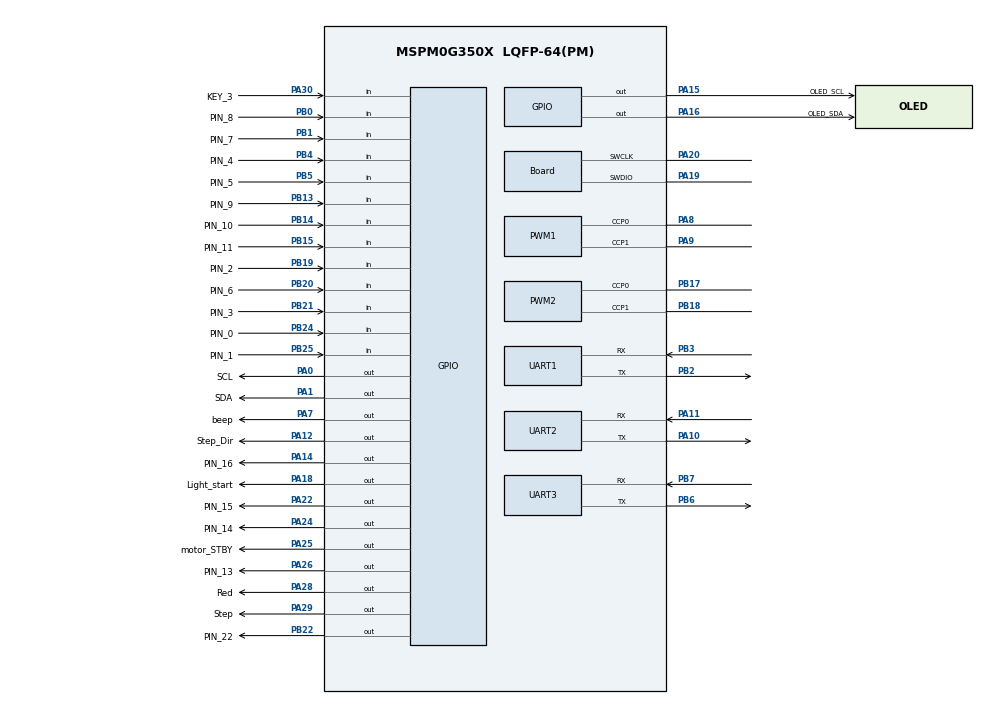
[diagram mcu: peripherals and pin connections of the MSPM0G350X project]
/**
 * @cliArgs --device "MSPM0G350X" --part "Default" --package "LQFP-64(PM)" --product "mspm0_sdk@2.03.00.07"
 * @versions {"tool":"1.22.0+3893"}
 */

/**
 * Import the modules used in this configuration.
 */
const GPIO          = scripting.addModule("/ti/driverlib/GPIO", {}, false);
const GPIO1         = GPIO.addInstance();
const GPIO2         = GPIO.addInstance();
const GPIO3         = GPIO.addInstance();
const GPIO4         = GPIO.addInstance();
const GPIO5         = GPIO.addInstance();
const GPIO6         = GPIO.addInstance();
const GPIO7         = GPIO.addInstance();
const PWM           = scripting.addModule("/ti/driverlib/PWM", {}, false);
const PWM1          = PWM.addInstance();
const PWM2          = PWM.addInstance();
const SYSCTL        = scripting.addModule("/ti/driverlib/SYSCTL");
const TIMER         = scripting.addModule("/ti/driverlib/TIMER", {}, false);
const TIMER1        = TIMER.addInstance();
const UART          = scripting.addModule("/ti/driverlib/UART", {}, false);
const UART1         = UART.addInstance();
const UART2         = UART.addInstance();
const UART3         = UART.addInstance();
const ProjectConfig = scripting.addModule("/ti/project_config/ProjectConfig");

/**
 * Write custom configuration values to the imported modules.
 */
const divider6       = system.clockTree["PLL_CLK2X_DIV"];
divider6.divideValue = 4;

const divider7       = system.clockTree["PLL_PDIV"];
divider7.divideValue = 2;

const divider9       = system.clockTree["UDIV"];
divider9.divideValue = 2;

const gate7  = system.clockTree["MFCLKGATE"];
gate7.enable = true;

const multiplier2         = system.clockTree["PLL_QDIV"];
multiplier2.multiplyValue = 10;

const mux8       = system.clockTree["HSCLKMUX"];
mux8.inputSelect = "HSCLKMUX_SYSPLL2X";

GPIO1.$name                         = "PORTA";
GPIO1.port                          = "PORTA";
GPIO1.associatedPins.create(8);
GPIO1.associatedPins[0].$name       = "OLED_SCL";
GPIO1.associatedPins[0].pin.$assign = "PA15";
GPIO1.associatedPins[1].$name       = "PIN_13";
GPIO1.associatedPins[1].pin.$assign = "PA26";
GPIO1.associatedPins[2].$name       = "PIN_14";
GPIO1.associatedPins[2].pin.$assign = "PA24";
GPIO1.associatedPins[3].$name       = "PIN_15";
GPIO1.associatedPins[3].pin.$assign = "PA22";
GPIO1.associatedPins[4].$name       = "PIN_16";
GPIO1.associatedPins[4].pin.$assign = "PA14";
GPIO1.associatedPins[5].$name       = "beep";
GPIO1.associatedPins[5].pin.$assign = "PA7";
GPIO1.associatedPins[6].$name       = "motor_STBY";
GPIO1.associatedPins[6].pin.$assign = "PA25";
GPIO1.associatedPins[7].$name       = "Light_start";
GPIO1.associatedPins[7].pin.$assign = "PA18";

const Board                       = scripting.addModule("/ti/driverlib/Board", {}, false);
Board.peripheral.$assign          = "DEBUGSS";
Board.peripheral.swclkPin.$assign = "PA20";
Board.peripheral.swdioPin.$assign = "PA19";

GPIO2.$name                         = "PORTB";
GPIO2.port                          = "PORTA";
GPIO2.associatedPins.create(4);
GPIO2.associatedPins[0].$name       = "OLED_SDA";
GPIO2.associatedPins[0].pin.$assign = "PA16";
GPIO2.associatedPins[1].$name       = "Red";
GPIO2.associatedPins[1].pin.$assign = "PA28";
GPIO2.associatedPins[2].$name       = "Step";
GPIO2.associatedPins[2].pin.$assign = "PA29";
GPIO2.associatedPins[3].$name       = "Step_Dir";
GPIO2.associatedPins[3].pin.$assign = "PA12";

GPIO3.$name                               = "GPIO_EncoderA";
GPIO3.port                                = "PORTB";
GPIO3.associatedPins.create(4);
GPIO3.associatedPins[0].$name             = "PIN_0";
GPIO3.associatedPins[0].direction         = "INPUT";
GPIO3.associatedPins[0].interruptEn       = true;
GPIO3.associatedPins[0].interruptPriority = "0";
GPIO3.associatedPins[0].polarity          = "RISE";
GPIO3.associatedPins[0].pin.$assign       = "PB24";
GPIO3.associatedPins[1].$name             = "PIN_1";
GPIO3.associatedPins[1].direction         = "INPUT";
GPIO3.associatedPins[1].polarity          = "RISE";
GPIO3.associatedPins[1].interruptEn       = true;
GPIO3.associatedPins[1].interruptPriority = "0";
GPIO3.associatedPins[1].pin.$assign       = "PB25";
GPIO3.associatedPins[2].$name             = "PIN_2";
GPIO3.associatedPins[2].direction         = "INPUT";
GPIO3.associatedPins[2].interruptEn       = true;
GPIO3.associatedPins[2].polarity          = "RISE";
GPIO3.associatedPins[2].interruptPriority = "0";
GPIO3.associatedPins[2].pin.$assign       = "PB19";
GPIO3.associatedPins[3].$name             = "PIN_3";
GPIO3.associatedPins[3].direction         = "INPUT";
GPIO3.associatedPins[3].interruptEn       = true;
GPIO3.associatedPins[3].interruptPriority = "0";
GPIO3.associatedPins[3].polarity          = "RISE";
GPIO3.associatedPins[3].pin.$assign       = "PB21";

GPIO4.$name                              = "GPIO_KEY";
GPIO4.port                               = "PORTA";
GPIO4.associatedPins.create(3);
GPIO4.associatedPins[0].direction        = "INPUT";
GPIO4.associatedPins[0].internalResistor = "PULL_UP";
GPIO4.associatedPins[0].$name            = "KEY_1";
GPIO4.associatedPins[0].assignedPin      = "27";
GPIO4.associatedPins[1].direction        = "INPUT";
GPIO4.associatedPins[1].internalResistor = "PULL_UP";
GPIO4.associatedPins[1].$name            = "KEY_2";
GPIO4.associatedPins[1].assignedPin      = "17";
GPIO4.associatedPins[2].direction        = "INPUT";
GPIO4.associatedPins[2].internalResistor = "PULL_UP";
GPIO4.associatedPins[2].$name            = "KEY_3";
GPIO4.associatedPins[2].assignedPin      = "30";
GPIO4.associatedPins[2].pin.$assign      = "PA30";

GPIO5.$name                         = "user_led";
GPIO5.port                          = "PORTB";
GPIO5.associatedPins[0].$name       = "PIN_22";
GPIO5.associatedPins[0].assignedPin = "22";
GPIO5.associatedPins[0].pin.$assign = "PB22";

GPIO6.$name                         = "HUIDU";
GPIO6.associatedPins.create(8);
GPIO6.associatedPins[0].$name       = "PIN_4";
GPIO6.associatedPins[0].direction   = "INPUT";
GPIO6.associatedPins[0].pin.$assign = "PB4";
GPIO6.associatedPins[1].$name       = "PIN_5";
GPIO6.associatedPins[1].direction   = "INPUT";
GPIO6.associatedPins[1].pin.$assign = "PB5";
GPIO6.associatedPins[2].$name       = "PIN_6";
GPIO6.associatedPins[2].direction   = "INPUT";
GPIO6.associatedPins[2].pin.$assign = "PB20";
GPIO6.associatedPins[3].$name       = "PIN_7";
GPIO6.associatedPins[3].direction   = "INPUT";
GPIO6.associatedPins[3].pin.$assign = "PB1";
GPIO6.associatedPins[4].$name       = "PIN_8";
GPIO6.associatedPins[4].direction   = "INPUT";
GPIO6.associatedPins[4].pin.$assign = "PB0";
GPIO6.associatedPins[5].$name       = "PIN_9";
GPIO6.associatedPins[5].direction   = "INPUT";
GPIO6.associatedPins[5].pin.$assign = "PB13";
GPIO6.associatedPins[6].$name       = "PIN_10";
GPIO6.associatedPins[6].direction   = "INPUT";
GPIO6.associatedPins[6].assignedPin = "14";
GPIO6.associatedPins[6].pin.$assign = "PB14";
GPIO6.associatedPins[7].$name       = "PIN_11";
GPIO6.associatedPins[7].direction   = "INPUT";
GPIO6.associatedPins[7].pin.$assign = "PB15";

GPIO7.$name                          = "GPIO_PORT";
GPIO7.associatedPins.create(2);
GPIO7.associatedPins[0].$name        = "SDA";
GPIO7.associatedPins[0].assignedPort = "PORTA";
GPIO7.associatedPins[0].assignedPin  = "1";
GPIO7.associatedPins[0].pin.$assign  = "PA1";
GPIO7.associatedPins[1].$name        = "SCL";
GPIO7.associatedPins[1].assignedPort = "PORTA";
GPIO7.associatedPins[1].assignedPin  = "0";
GPIO7.associatedPins[1].pin.$assign  = "PA0";

PWM1.$name                              = "Motor";
PWM1.timerCount                         = 32000;
PWM1.interruptPriority                  = "3";
PWM1.peripheral.$assign                 = "TIMA0";
PWM1.peripheral.ccp0Pin.$assign         = "PA8";
PWM1.peripheral.ccp1Pin.$assign         = "PA9";
PWM1.PWM_CHANNEL_0.$name                = "ti_driverlib_pwm_PWMTimerCC0";
PWM1.PWM_CHANNEL_1.$name                = "ti_driverlib_pwm_PWMTimerCC1";
PWM1.ccp0PinConfig.direction            = scripting.forceWrite("OUTPUT");
PWM1.ccp0PinConfig.hideOutputInversion  = scripting.forceWrite(false);
PWM1.ccp0PinConfig.onlyInternalResistor = scripting.forceWrite(false);
PWM1.ccp0PinConfig.passedPeripheralType = scripting.forceWrite("Digital");
PWM1.ccp0PinConfig.$name                = "ti_driverlib_gpio_GPIOPinGeneric2";
PWM1.ccp1PinConfig.direction            = scripting.forceWrite("OUTPUT");
PWM1.ccp1PinConfig.hideOutputInversion  = scripting.forceWrite(false);
PWM1.ccp1PinConfig.onlyInternalResistor = scripting.forceWrite(false);
PWM1.ccp1PinConfig.passedPeripheralType = scripting.forceWrite("Digital");
PWM1.ccp1PinConfig.$name                = "ti_driverlib_gpio_GPIOPinGeneric3";

PWM2.$name                              = "Steer";
PWM2.timerStartTimer                    = true;
PWM2.clockDivider                       = 4;
PWM2.clockSource                        = "MFCLK";
PWM2.timerCount                         = 20000;
PWM2.peripheral.$assign                 = "TIMA1";
PWM2.peripheral.ccp0Pin.$assign         = "PB17";
PWM2.peripheral.ccp1Pin.$assign         = "PB18";
PWM2.PWM_CHANNEL_0.$name                = "ti_driverlib_pwm_PWMTimerCC2";
PWM2.PWM_CHANNEL_0.invert               = true;
PWM2.PWM_CHANNEL_1.$name                = "ti_driverlib_pwm_PWMTimerCC3";
PWM2.PWM_CHANNEL_1.invert               = true;
PWM2.ccp0PinConfig.direction            = scripting.forceWrite("OUTPUT");
PWM2.ccp0PinConfig.hideOutputInversion  = scripting.forceWrite(false);
PWM2.ccp0PinConfig.onlyInternalResistor = scripting.forceWrite(false);
PWM2.ccp0PinConfig.passedPeripheralType = scripting.forceWrite("Digital");
PWM2.ccp0PinConfig.$name                = "ti_driverlib_gpio_GPIOPinGeneric8";
PWM2.ccp1PinConfig.direction            = scripting.forceWrite("OUTPUT");
PWM2.ccp1PinConfig.hideOutputInversion  = scripting.forceWrite(false);
PWM2.ccp1PinConfig.onlyInternalResistor = scripting.forceWrite(false);
PWM2.ccp1PinConfig.passedPeripheralType = scripting.forceWrite("Digital");
PWM2.ccp1PinConfig.$name                = "ti_driverlib_gpio_GPIOPinGeneric9";

SYSCTL.clockTreeEn = true;

TIMER1.$name              = "TIMER_0";
TIMER1.timerMode          = "PERIODIC";
TIMER1.interrupts         = ["ZERO"];
TIMER1.timerClkPrescale   = 256;
TIMER1.timerStartTimer    = true;
TIMER1.timerPeriod        = "2ms";
TIMER1.peripheral.$assign = "TIMG6";

UART1.enabledInterrupts                = ["RX","TX"];
UART1.$name                            = "UART_3";
UART1.targetBaudRate                   = 115200;
UART1.peripheral.$assign               = "UART3";
UART1.peripheral.rxPin.$assign         = "PB3";
UART1.peripheral.txPin.$assign         = "PB2";
UART1.txPinConfig.direction            = scripting.forceWrite("OUTPUT");
UART1.txPinConfig.hideOutputInversion  = scripting.forceWrite(false);
UART1.txPinConfig.onlyInternalResistor = scripting.forceWrite(false);
UART1.txPinConfig.passedPeripheralType = scripting.forceWrite("Digital");
UART1.txPinConfig.$name                = "ti_driverlib_gpio_GPIOPinGeneric0";
UART1.rxPinConfig.hideOutputInversion  = scripting.forceWrite(false);
UART1.rxPinConfig.onlyInternalResistor = scripting.forceWrite(false);
UART1.rxPinConfig.passedPeripheralType = scripting.forceWrite("Digital");
UART1.rxPinConfig.$name                = "ti_driverlib_gpio_GPIOPinGeneric1";

UART2.$name                            = "UART_0";
UART2.enabledInterrupts                = ["RX","TX"];
UART2.peripheral.$assign               = "UART0";
UART2.peripheral.rxPin.$assign         = "PA11";
UART2.peripheral.txPin.$assign         = "PA10";
UART2.txPinConfig.direction            = scripting.forceWrite("OUTPUT");
UART2.txPinConfig.hideOutputInversion  = scripting.forceWrite(false);
UART2.txPinConfig.onlyInternalResistor = scripting.forceWrite(false);
UART2.txPinConfig.passedPeripheralType = scripting.forceWrite("Digital");
UART2.txPinConfig.$name                = "ti_driverlib_gpio_GPIOPinGeneric4";
UART2.rxPinConfig.hideOutputInversion  = scripting.forceWrite(false);
UART2.rxPinConfig.onlyInternalResistor = scripting.forceWrite(false);
UART2.rxPinConfig.passedPeripheralType = scripting.forceWrite("Digital");
UART2.rxPinConfig.$name                = "ti_driverlib_gpio_GPIOPinGeneric5";

UART3.$name                            = "UART_1";
UART3.targetBaudRate                   = 115200;
UART3.uartClkSrc                       = "MFCLK";
UART3.enabledInterrupts                = ["RX","TX"];
UART3.peripheral.$assign               = "UART1";
UART3.peripheral.rxPin.$assign         = "PB7";
UART3.peripheral.txPin.$assign         = "PB6";
UART3.txPinConfig.direction            = scripting.forceWrite("OUTPUT");
UART3.txPinConfig.hideOutputInversion  = scripting.forceWrite(false);
UART3.txPinConfig.onlyInternalResistor = scripting.forceWrite(false);
UART3.txPinConfig.passedPeripheralType = scripting.forceWrite("Digital");
UART3.txPinConfig.$name                = "ti_driverlib_gpio_GPIOPinGeneric6";
UART3.rxPinConfig.hideOutputInversion  = scripting.forceWrite(false);
UART3.rxPinConfig.onlyInternalResistor = scripting.forceWrite(false);
UART3.rxPinConfig.passedPeripheralType = scripting.forceWrite("Digital");
UART3.rxPinConfig.$name                = "ti_driverlib_gpio_GPIOPinGeneric7";

ProjectConfig.migrationCondition = true;

/**
 * Pinmux solution for unlocked pins/peripherals. This ensures that minor changes to the automatic solver in a future
 * version of the tool will not impact the pinmux you originally saw.  These lines can be completely deleted in order to
 * re-solve from scratch.
 */
GPIO4.associatedPins[0].pin.$suggestSolution = "PA27";
GPIO4.associatedPins[1].pin.$suggestSolution = "PA17";
